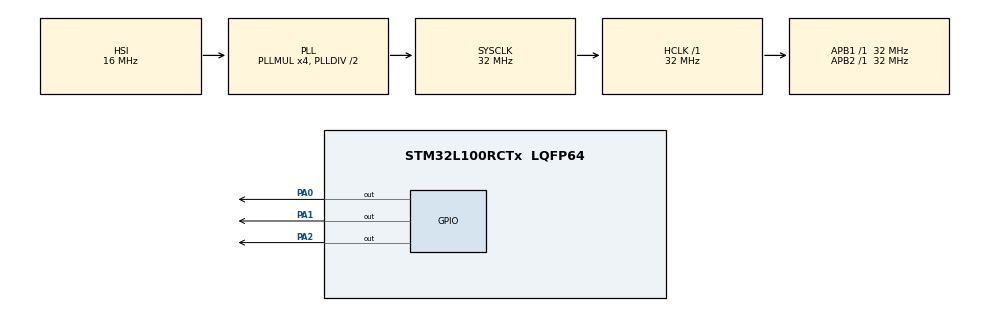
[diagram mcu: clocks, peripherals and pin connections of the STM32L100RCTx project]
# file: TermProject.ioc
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Mcu.Family=STM32L1
Mcu.Name=STM32L100RCTx
Mcu.Package=LQFP64
NVIC.PriorityGroup=NVIC_PRIORITYGROUP_4
PA0-WKUP1.Signal=GPIO_Output
PA1.Signal=GPIO_Output
PA13.Mode=Serial_Wire
PA13.Signal=SYS_JTMS-SWDIO
PA14.Mode=Serial_Wire
PA14.Signal=SYS_JTCK-SWCLK
PA2.Signal=GPIO_Output
PH0-OSC_IN.Mode=HSE-External-Oscillator
PH0-OSC_IN.Signal=RCC_OSC_IN
PH1-OSC_OUT.Mode=HSE-External-Oscillator
PH1-OSC_OUT.Signal=RCC_OSC_OUT
ProjectManager.HeapSize=0x200
ProjectManager.StackSize=0x400
ProjectManager.TargetToolchain=MDK-ARM V5.32
RCC.48MHZClocksFreq_Value=32000000
RCC.AHBFreq_Value=32000000
RCC.APB1Freq_Value=32000000
RCC.APB1TimFreq_Value=32000000
RCC.APB2Freq_Value=32000000
RCC.APB2TimFreq_Value=32000000
RCC.HCLKFreq_Value=32000000
RCC.HSE_VALUE=24000000
RCC.HSI_VALUE=16000000
RCC.LSE_VALUE=32768
RCC.MSI_VALUE=2097000
RCC.PLLMUL=RCC_PLL_MUL4
RCC.SYSCLKFreq_VALUE=32000000
RCC.SYSCLKSource=RCC_SYSCLKSOURCE_PLLCLK
RCC.VCOOutputFreq_Value=64000000
board=custom

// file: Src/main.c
/* USER CODE BEGIN Header */
/**
  ******************************************************************************
  * @file           : main.c
  * @brief          : Main program body
  ******************************************************************************
  * @attention
  *
  * Copyright (c) 2022 STMicroelectronics.
  * All rights reserved.
  *
  * This software is licensed under terms that can be found in the LICENSE file
  * in the root directory of this software component.
  * If no LICENSE file comes with this software, it is provided AS-IS.
  *
  ******************************************************************************
  */
/* USER CODE END Header */
#include "main.h"

/* USER CODE BEGIN PM */
void port_yaz(int s){
		GPIOA -> ODR = s;
}
void write_byte(uint8_t byte){
	for(int i =0; i<8; i++){
		HAL_GPIO_WritePin(GPIOA,GPIO_PIN_0,GPIO_PIN_RESET);
		HAL_GPIO_WritePin(GPIOA,GPIO_PIN_2,byte &0x80);
		byte = byte<<1;
		HAL_GPIO_WritePin(GPIOA,GPIO_PIN_0,GPIO_PIN_SET);
	}
}

void write_max(uint8_t address,uint8_t data){
		HAL_GPIO_WritePin(GPIOA,GPIO_PIN_1,GPIO_PIN_RESET);
		write_byte(address);
		write_byte(data);
		HAL_GPIO_WritePin(GPIOA,GPIO_PIN_1,GPIO_PIN_SET);
}
void max_init(void)
{
 write_max(0x09, 0x00);       //  no decoding
 write_max(0x0a, 0x03);       //  brightness intensity
 write_max(0x0b, 0x07);       //  scan limit = 8 LEDs
 write_max(0x0c, 0x01);       //  power down =0,normal mode = 1
 write_max(0x0f, 0x00);       //  no test display
}
/* USER CODE END PM */

void SystemClock_Config(void);
static void MX_GPIO_Init(void);

/* USER CODE BEGIN 0 */
uint8_t disp1ay[48][8]={
{0xFF,0xFF,0xFF,0xFF,0xFF,0xFF,0xFF,0xFF},//FULL
{0xFE,0xFF,0xFF,0xFF,0xFF,0xFF,0xFF,0xFF},
{0xFC,0xFF,0xFF,0xFF,0xFF,0xFF,0xFF,0xFF},
{0xFC,0xFE,0xFF,0xFF,0xFF,0xFF,0xFF,0xFF},

{0x3C,0x42,0x42,0x42,0x42,0x42,0x42,0x3C},//0
{0x10,0x30,0x50,0x10,0x10,0x10,0x10,0x7c},//1
{0x7E,0x2,0x2,0x7E,0x40,0x40,0x40,0x7E},//2
{0x3E,0x2,0x2,0x3E,0x2,0x2,0x3E,0x0},//3
{0x8,0x18,0x28,0x48,0xFE,0x8,0x8,0x8},//4
{0x3C,0x20,0x20,0x3C,0x4,0x4,0x3C,0x0},//5
{0x3C,0x20,0x20,0x3C,0x24,0x24,0x3C,0x0},//6
{0x3E,0x22,0x4,0x8,0x8,0x8,0x8,0x8},//7
{0x0,0x3E,0x22,0x22,0x3E,0x22,0x22,0x3E},//8
{0x3E,0x22,0x22,0x3E,0x2,0x2,0x2,0x3E},//9
{0x18,0x24,0x42,0x42,0x7E,0x42,0x42,0x42},//A
{0x3C,0x22,0x22,0x3c,0x22,0x22,0x3C,0x0},//B
{0x3C,0x40,0x40,0x40,0x40,0x40,0x40,0x3C},//C
{0x7C,0x22,0x22,0x22,0x22,0x22,0x22,0x7C},//D
{0x7C,0x40,0x40,0x7C,0x40,0x40,0x40,0x7C},//E
{0x7C,0x40,0x40,0x7C,0x40,0x40,0x40,0x40},//F
{0x3C,0x40,0x40,0x40,0x4c,0x44,0x44,0x3C},//G
{0x44,0x44,0x44,0x7C,0x44,0x44,0x44,0x44},//H
{0x7C,0x10,0x10,0x10,0x10,0x10,0x10,0x7C},//I
{0x3C,0x8,0x8,0x8,0x8,0x8,0x48,0x30},//J
{0x0,0x24,0x28,0x30,0x20,0x30,0x28,0x24},//K
{0x40,0x40,0x40,0x40,0x40,0x40,0x40,0x7C},//L
{0x81,0xC3,0xA5,0x99,0x81,0x81,0x81,0x81},//M
{0x0,0x42,0x62,0x52,0x4A,0x46,0x42,0x0},//N
{0x3C,0x42,0x42,0x42,0x42,0x42,0x42,0x3C},//O
{0x3C,0x22,0x22,0x22,0x3C,0x20,0x20,0x20},//P
{0x1C,0x22,0x22,0x22,0x22,0x26,0x22,0x1D},//Q
{0x3C,0x22,0x22,0x22,0x3C,0x24,0x22,0x21},//R
{0x0,0x1E,0x20,0x20,0x3E,0x2,0x2,0x3C},//S
{0x0,0x3E,0x8,0x8,0x8,0x8,0x8,0x8},//T
{0x42,0x42,0x42,0x42,0x42,0x42,0x22,0x1C},//U
{0x42,0x42,0x42,0x42,0x42,0x42,0x24,0x18},//V
{0x0,0x49,0x49,0x49,0x49,0x2A,0x1C,0x0},//W
{0x0,0x41,0x22,0x14,0x8,0x14,0x22,0x41},//X
{0x41,0x22,0x14,0x8,0x8,0x8,0x8,0x8},//Y
{0x0,0x7F,0x2,0x4,0x8,0x10,0x20,0x7F},//Z
};

/* USER CODE END 0 */

int main(void)
{

  /* MCU Configuration--------------------------------------------------------*/

  /* Reset of all peripherals, Initializes the Flash interface and the Systick. */
  HAL_Init();

  /* Configure the system clock */
  SystemClock_Config();

  /* Initialize all configured peripherals */
  MX_GPIO_Init();
  /* USER CODE BEGIN 2 */
	max_init();
  /* USER CODE END 2 */

  /* Infinite loop */
  while (1)
  {

    /* USER CODE BEGIN 3 */
		/*HAL_GPIO_WritePin(GPIOA,GPIO_PIN_0,GPIO_PIN_RESET);
		HAL_GPIO_WritePin(GPIOA,GPIO_PIN_1,GPIO_PIN_RESET);
		port_yaz(0x01);
		HAL_GPIO_WritePin(GPIOA,GPIO_PIN_1,GPIO_PIN_SET);

		HAL_GPIO_WritePin(GPIOA,GPIO_PIN_0,GPIO_PIN_RESET);
		HAL_GPIO_WritePin(GPIOA,GPIO_PIN_1,GPIO_PIN_RESET);
		port_yaz(0x07);
		HAL_GPIO_WritePin(GPIOA,GPIO_PIN_1,GPIO_PIN_SET);

		HAL_GPIO_WritePin(GPIOA,GPIO_PIN_0,GPIO_PIN_SET);*/
		for (int j=0; j<4; j++)
		{
			for (int i=1; i<9; i++)
			{
			//write_max (i , disp1ay[j][i-1]);
			write_max (i , disp1ay[j][i-1]);

			}
			HAL_Delay (700);
		}
	//	HAL_Delay(3000);

	}
  /* USER CODE END 3 */
}

void SystemClock_Config(void)
{
  RCC_OscInitTypeDef RCC_OscInitStruct = {0};
  RCC_ClkInitTypeDef RCC_ClkInitStruct = {0};

  /** Configure the main internal regulator output voltage
  */
  __HAL_PWR_VOLTAGESCALING_CONFIG(PWR_REGULATOR_VOLTAGE_SCALE1);
  /** Initializes the RCC Oscillators according to the specified parameters
  * in the RCC_OscInitTypeDef structure.
  */
  RCC_OscInitStruct.OscillatorType = RCC_OSCILLATORTYPE_HSI;
  RCC_OscInitStruct.HSIState = RCC_HSI_ON;
  RCC_OscInitStruct.HSICalibrationValue = RCC_HSICALIBRATION_DEFAULT;
  RCC_OscInitStruct.PLL.PLLState = RCC_PLL_ON;
  RCC_OscInitStruct.PLL.PLLSource = RCC_PLLSOURCE_HSI;
  RCC_OscInitStruct.PLL.PLLMUL = RCC_PLL_MUL4;
  RCC_OscInitStruct.PLL.PLLDIV = RCC_PLL_DIV2;
  if (HAL_RCC_OscConfig(&RCC_OscInitStruct) != HAL_OK)
  {
    Error_Handler();
  }
  /** Initializes the CPU, AHB and APB buses clocks
  */
  RCC_ClkInitStruct.ClockType = RCC_CLOCKTYPE_HCLK|RCC_CLOCKTYPE_SYSCLK
                              |RCC_CLOCKTYPE_PCLK1|RCC_CLOCKTYPE_PCLK2;
  RCC_ClkInitStruct.SYSCLKSource = RCC_SYSCLKSOURCE_PLLCLK;
  RCC_ClkInitStruct.AHBCLKDivider = RCC_SYSCLK_DIV1;
  RCC_ClkInitStruct.APB1CLKDivider = RCC_HCLK_DIV1;
  RCC_ClkInitStruct.APB2CLKDivider = RCC_HCLK_DIV1;

  if (HAL_RCC_ClockConfig(&RCC_ClkInitStruct, FLASH_LATENCY_1) != HAL_OK)
  {
    Error_Handler();
  }
}

static void MX_GPIO_Init(void)
{
  GPIO_InitTypeDef GPIO_InitStruct = {0};

  /* GPIO Ports Clock Enable */
  __HAL_RCC_GPIOH_CLK_ENABLE();
  __HAL_RCC_GPIOA_CLK_ENABLE();

  /*Configure GPIO pin Output Level */
  HAL_GPIO_WritePin(GPIOA, GPIO_PIN_0|GPIO_PIN_1|GPIO_PIN_2, GPIO_PIN_RESET);

  /*Configure GPIO pins : PA0 PA1 PA2 */
  GPIO_InitStruct.Pin = GPIO_PIN_0|GPIO_PIN_1|GPIO_PIN_2;
  GPIO_InitStruct.Mode = GPIO_MODE_OUTPUT_PP;
  GPIO_InitStruct.Pull = GPIO_NOPULL;
  GPIO_InitStruct.Speed = GPIO_SPEED_FREQ_LOW;
  HAL_GPIO_Init(GPIOA, &GPIO_InitStruct);

}

void Error_Handler(void)
{
  __disable_irq();
  while (1)
  {
  }
}
